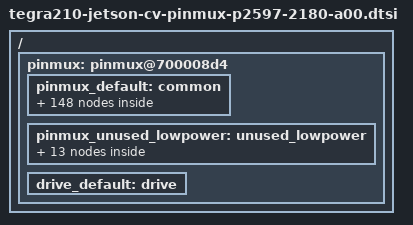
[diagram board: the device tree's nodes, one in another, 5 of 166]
/*
 * Copyright (c) 2015, NVIDIA CORPORATION.  All rights reserved.
 *
 * This program is free software; you can redistribute it and/or modify
 * it under the terms of the GNU General Public License as published by
 * the Free Software Foundation; either version 2 of the License, or
 * (at your option) any later version.
 *
 * This program is distributed in the hope that it will be useful, but WITHOUT
 * ANY WARRANTY; without even the implied warranty of MERCHANTABILITY or
 * FITNESS FOR A PARTICULAR PURPOSE.  See the GNU General Public License for
 * more details.
 *
 * You should have received a copy of the GNU General Public License along
 * with this program; if not, write to the Free Software Foundation, Inc.,
 * 51 Franklin Street, Fifth Floor, Boston, MA  02110-1301, USA.
 */

#include <dt-bindings/pinctrl/pinctrl-tegra.h>

/ {
	pinmux: pinmux@700008d4 {
		status = "okay";
		pinctrl-names = "default", "drive", "unused";
		pinctrl-0 = <&pinmux_default>;
		pinctrl-1 = <&drive_default>;
		pinctrl-2 = <&pinmux_unused_lowpower>;

		pinmux_default: common {
			/* SFIO Pin Configuration */
			aud_mclk {
				nvidia,pins = "aud_mclk";
				nvidia,function = "aud";
				nvidia,pull = <TEGRA_PIN_PULL_NONE>;
				nvidia,tristate = <TEGRA_PIN_DISABLE>;
				nvidia,enable-input = <TEGRA_PIN_DISABLE>;
			};

			dap1_din {
				nvidia,pins = "dap1_din";
				nvidia,function = "i2s1";
				nvidia,pull = <TEGRA_PIN_PULL_NONE>;
				nvidia,tristate = <TEGRA_PIN_DISABLE>;
				nvidia,enable-input = <TEGRA_PIN_ENABLE>;
			};

			dap1_dout {
				nvidia,pins = "dap1_dout";
				nvidia,function = "i2s1";
				nvidia,pull = <TEGRA_PIN_PULL_NONE>;
				nvidia,tristate = <TEGRA_PIN_DISABLE>;
				nvidia,enable-input = <TEGRA_PIN_ENABLE>;
			};

			dap1_fs {
				nvidia,pins = "dap1_fs";
				nvidia,function = "i2s1";
				nvidia,pull = <TEGRA_PIN_PULL_NONE>;
				nvidia,tristate = <TEGRA_PIN_DISABLE>;
				nvidia,enable-input = <TEGRA_PIN_ENABLE>;
			};

			dap1_sclk {
				nvidia,pins = "dap1_sclk";
				nvidia,function = "i2s1";
				nvidia,pull = <TEGRA_PIN_PULL_NONE>;
				nvidia,tristate = <TEGRA_PIN_DISABLE>;
				nvidia,enable-input = <TEGRA_PIN_ENABLE>;
			};

			pk0 {
				nvidia,pins = "pk0";
				nvidia,function = "i2s5b";
				nvidia,pull = <TEGRA_PIN_PULL_NONE>;
				nvidia,tristate = <TEGRA_PIN_DISABLE>;
				nvidia,enable-input = <TEGRA_PIN_ENABLE>;
			};

			pk1 {
				nvidia,pins = "pk1";
				nvidia,function = "i2s5b";
				nvidia,pull = <TEGRA_PIN_PULL_NONE>;
				nvidia,tristate = <TEGRA_PIN_DISABLE>;
				nvidia,enable-input = <TEGRA_PIN_ENABLE>;
			};

			pk2 {
				nvidia,pins = "pk2";
				nvidia,function = "i2s5b";
				nvidia,pull = <TEGRA_PIN_PULL_NONE>;
				nvidia,tristate = <TEGRA_PIN_DISABLE>;
				nvidia,enable-input = <TEGRA_PIN_ENABLE>;
			};

			pk3 {
				nvidia,pins = "pk3";
				nvidia,function = "i2s5b";
				nvidia,pull = <TEGRA_PIN_PULL_NONE>;
				nvidia,tristate = <TEGRA_PIN_DISABLE>;
				nvidia,enable-input = <TEGRA_PIN_ENABLE>;
			};

			dmic1_clk {
				nvidia,pins = "dmic1_clk";
				nvidia,function = "i2s3";
				nvidia,pull = <TEGRA_PIN_PULL_NONE>;
				nvidia,tristate = <TEGRA_PIN_DISABLE>;
				nvidia,enable-input = <TEGRA_PIN_ENABLE>;
			};

			dmic1_dat {
				nvidia,pins = "dmic1_dat";
				nvidia,function = "i2s3";
				nvidia,pull = <TEGRA_PIN_PULL_NONE>;
				nvidia,tristate = <TEGRA_PIN_DISABLE>;
				nvidia,enable-input = <TEGRA_PIN_ENABLE>;
			};

			dmic2_clk {
				nvidia,pins = "dmic2_clk";
				nvidia,function = "i2s3";
				nvidia,pull = <TEGRA_PIN_PULL_NONE>;
				nvidia,tristate = <TEGRA_PIN_DISABLE>;
				nvidia,enable-input = <TEGRA_PIN_ENABLE>;
			};

			dmic2_dat {
				nvidia,pins = "dmic2_dat";
				nvidia,function = "i2s3";
				nvidia,pull = <TEGRA_PIN_PULL_NONE>;
				nvidia,tristate = <TEGRA_PIN_DISABLE>;
				nvidia,enable-input = <TEGRA_PIN_ENABLE>;
			};

			dap4_din {
				nvidia,pins = "dap4_din";
				nvidia,function = "i2s4b";
				nvidia,pull = <TEGRA_PIN_PULL_NONE>;
				nvidia,tristate = <TEGRA_PIN_DISABLE>;
				nvidia,enable-input = <TEGRA_PIN_ENABLE>;
			};

			dap4_dout {
				nvidia,pins = "dap4_dout";
				nvidia,function = "i2s4b";
				nvidia,pull = <TEGRA_PIN_PULL_NONE>;
				nvidia,tristate = <TEGRA_PIN_DISABLE>;
				nvidia,enable-input = <TEGRA_PIN_ENABLE>;
			};

			dap4_fs {
				nvidia,pins = "dap4_fs";
				nvidia,function = "i2s4b";
				nvidia,pull = <TEGRA_PIN_PULL_NONE>;
				nvidia,tristate = <TEGRA_PIN_DISABLE>;
				nvidia,enable-input = <TEGRA_PIN_ENABLE>;
			};

			dap4_sclk {
				nvidia,pins = "dap4_sclk";
				nvidia,function = "i2s4b";
				nvidia,pull = <TEGRA_PIN_PULL_NONE>;
				nvidia,tristate = <TEGRA_PIN_DISABLE>;
				nvidia,enable-input = <TEGRA_PIN_ENABLE>;
			};

			dmic3_clk {
				nvidia,pins = "dmic3_clk";
				nvidia,function = "dmic3";
				nvidia,pull = <TEGRA_PIN_PULL_NONE>;
				nvidia,tristate = <TEGRA_PIN_DISABLE>;
				nvidia,enable-input = <TEGRA_PIN_DISABLE>;
			};

			dmic3_dat {
				nvidia,pins = "dmic3_dat";
				nvidia,function = "dmic3";
				nvidia,pull = <TEGRA_PIN_PULL_UP>;
				nvidia,tristate = <TEGRA_PIN_DISABLE>;
				nvidia,enable-input = <TEGRA_PIN_ENABLE>;
			};

			gen1_i2c_scl {
				nvidia,pins = "gen1_i2c_scl";
				nvidia,function = "i2c1";
				nvidia,pull = <TEGRA_PIN_PULL_NONE>;
				nvidia,tristate = <TEGRA_PIN_DISABLE>;
				nvidia,enable-input = <TEGRA_PIN_ENABLE>;
				nvidia,io-high-voltage = <TEGRA_PIN_DISABLE>;
			};

			gen1_i2c_sda {
				nvidia,pins = "gen1_i2c_sda";
				nvidia,function = "i2c1";
				nvidia,pull = <TEGRA_PIN_PULL_NONE>;
				nvidia,tristate = <TEGRA_PIN_DISABLE>;
				nvidia,enable-input = <TEGRA_PIN_ENABLE>;
				nvidia,io-high-voltage = <TEGRA_PIN_DISABLE>;
			};

			gen2_i2c_scl {
				nvidia,pins = "gen2_i2c_scl";
				nvidia,function = "i2c2";
				nvidia,pull = <TEGRA_PIN_PULL_NONE>;
				nvidia,tristate = <TEGRA_PIN_DISABLE>;
				nvidia,enable-input = <TEGRA_PIN_ENABLE>;
				nvidia,io-high-voltage = <TEGRA_PIN_ENABLE>;
			};

			gen2_i2c_sda {
				nvidia,pins = "gen2_i2c_sda";
				nvidia,function = "i2c2";
				nvidia,pull = <TEGRA_PIN_PULL_NONE>;
				nvidia,tristate = <TEGRA_PIN_DISABLE>;
				nvidia,enable-input = <TEGRA_PIN_ENABLE>;
				nvidia,io-high-voltage = <TEGRA_PIN_ENABLE>;
			};

			cam_i2c_scl {
				nvidia,pins = "cam_i2c_scl";
				nvidia,function = "i2cvi";
				nvidia,pull = <TEGRA_PIN_PULL_NONE>;
				nvidia,tristate = <TEGRA_PIN_DISABLE>;
				nvidia,enable-input = <TEGRA_PIN_ENABLE>;
				nvidia,io-high-voltage = <TEGRA_PIN_DISABLE>;
			};

			cam_i2c_sda {
				nvidia,pins = "cam_i2c_sda";
				nvidia,function = "i2cvi";
				nvidia,pull = <TEGRA_PIN_PULL_NONE>;
				nvidia,tristate = <TEGRA_PIN_DISABLE>;
				nvidia,enable-input = <TEGRA_PIN_ENABLE>;
				nvidia,io-high-voltage = <TEGRA_PIN_DISABLE>;
			};

			cam1_mclk {
				nvidia,pins = "cam1_mclk";
				nvidia,function = "extperiph3";
				nvidia,pull = <TEGRA_PIN_PULL_NONE>;
				nvidia,tristate = <TEGRA_PIN_DISABLE>;
				nvidia,enable-input = <TEGRA_PIN_DISABLE>;
			};

			cam2_mclk {
				nvidia,pins = "cam2_mclk";
				nvidia,function = "extperiph3";
				nvidia,pull = <TEGRA_PIN_PULL_NONE>;
				nvidia,tristate = <TEGRA_PIN_DISABLE>;
				nvidia,enable-input = <TEGRA_PIN_DISABLE>;
			};

			pex_l0_clkreq_n {
				nvidia,pins = "pex_l0_clkreq_n";
				nvidia,function = "pe0";
				nvidia,pull = <TEGRA_PIN_PULL_NONE>;
				nvidia,tristate = <TEGRA_PIN_DISABLE>;
				nvidia,enable-input = <TEGRA_PIN_ENABLE>;
				nvidia,io-high-voltage = <TEGRA_PIN_ENABLE>;
			};

			pex_l0_rst_n {
				nvidia,pins = "pex_l0_rst_n";
				nvidia,function = "pe0";
				nvidia,pull = <TEGRA_PIN_PULL_NONE>;
				nvidia,tristate = <TEGRA_PIN_DISABLE>;
				nvidia,enable-input = <TEGRA_PIN_DISABLE>;
				nvidia,io-high-voltage = <TEGRA_PIN_ENABLE>;
			};

			pex_l1_clkreq_n {
				nvidia,pins = "pex_l1_clkreq_n";
				nvidia,function = "pe1";
				nvidia,pull = <TEGRA_PIN_PULL_NONE>;
				nvidia,tristate = <TEGRA_PIN_DISABLE>;
				nvidia,enable-input = <TEGRA_PIN_ENABLE>;
				nvidia,io-high-voltage = <TEGRA_PIN_ENABLE>;
			};

			pex_l1_rst_n {
				nvidia,pins = "pex_l1_rst_n";
				nvidia,function = "pe1";
				nvidia,pull = <TEGRA_PIN_PULL_NONE>;
				nvidia,tristate = <TEGRA_PIN_DISABLE>;
				nvidia,enable-input = <TEGRA_PIN_DISABLE>;
				nvidia,io-high-voltage = <TEGRA_PIN_ENABLE>;
			};

			pex_wake_n {
				nvidia,pins = "pex_wake_n";
				nvidia,function = "pe";
				nvidia,pull = <TEGRA_PIN_PULL_NONE>;
				nvidia,tristate = <TEGRA_PIN_DISABLE>;
				nvidia,enable-input = <TEGRA_PIN_ENABLE>;
				nvidia,io-high-voltage = <TEGRA_PIN_ENABLE>;
			};

			pa6 {
				nvidia,pins = "pa6";
				nvidia,function = "sata";
				nvidia,pull = <TEGRA_PIN_PULL_NONE>;
				nvidia,tristate = <TEGRA_PIN_DISABLE>;
				nvidia,enable-input = <TEGRA_PIN_DISABLE>;
			};

			sdmmc1_clk {
				nvidia,pins = "sdmmc1_clk";
				nvidia,function = "sdmmc1";
				nvidia,pull = <TEGRA_PIN_PULL_NONE>;
				nvidia,tristate = <TEGRA_PIN_DISABLE>;
				nvidia,enable-input = <TEGRA_PIN_ENABLE>;
			};

			sdmmc1_cmd {
				nvidia,pins = "sdmmc1_cmd";
				nvidia,function = "sdmmc1";
				nvidia,pull = <TEGRA_PIN_PULL_UP>;
				nvidia,tristate = <TEGRA_PIN_DISABLE>;
				nvidia,enable-input = <TEGRA_PIN_ENABLE>;
			};

			sdmmc1_dat0 {
				nvidia,pins = "sdmmc1_dat0";
				nvidia,function = "sdmmc1";
				nvidia,pull = <TEGRA_PIN_PULL_UP>;
				nvidia,tristate = <TEGRA_PIN_DISABLE>;
				nvidia,enable-input = <TEGRA_PIN_ENABLE>;
			};

			sdmmc1_dat1 {
				nvidia,pins = "sdmmc1_dat1";
				nvidia,function = "sdmmc1";
				nvidia,pull = <TEGRA_PIN_PULL_UP>;
				nvidia,tristate = <TEGRA_PIN_DISABLE>;
				nvidia,enable-input = <TEGRA_PIN_ENABLE>;
			};

			sdmmc1_dat2 {
				nvidia,pins = "sdmmc1_dat2";
				nvidia,function = "sdmmc1";
				nvidia,pull = <TEGRA_PIN_PULL_UP>;
				nvidia,tristate = <TEGRA_PIN_DISABLE>;
				nvidia,enable-input = <TEGRA_PIN_ENABLE>;
			};

			sdmmc1_dat3 {
				nvidia,pins = "sdmmc1_dat3";
				nvidia,function = "sdmmc1";
				nvidia,pull = <TEGRA_PIN_PULL_UP>;
				nvidia,tristate = <TEGRA_PIN_DISABLE>;
				nvidia,enable-input = <TEGRA_PIN_ENABLE>;
			};

			pz1 {
				nvidia,pins = "pz1";
				nvidia,function = "sdmmc1";
				nvidia,pull = <TEGRA_PIN_PULL_UP>;
				nvidia,tristate = <TEGRA_PIN_DISABLE>;
				nvidia,enable-input = <TEGRA_PIN_ENABLE>;
			};

			pz4 {
				nvidia,pins = "pz4";
				nvidia,function = "sdmmc1";
				nvidia,pull = <TEGRA_PIN_PULL_UP>;
				nvidia,tristate = <TEGRA_PIN_DISABLE>;
				nvidia,enable-input = <TEGRA_PIN_ENABLE>;
			};

			sdmmc3_clk {
				nvidia,pins = "sdmmc3_clk";
				nvidia,function = "sdmmc3";
				nvidia,pull = <TEGRA_PIN_PULL_NONE>;
				nvidia,tristate = <TEGRA_PIN_DISABLE>;
				nvidia,enable-input = <TEGRA_PIN_ENABLE>;
			};

			sdmmc3_cmd {
				nvidia,pins = "sdmmc3_cmd";
				nvidia,function = "sdmmc3";
				nvidia,pull = <TEGRA_PIN_PULL_UP>;
				nvidia,tristate = <TEGRA_PIN_DISABLE>;
				nvidia,enable-input = <TEGRA_PIN_ENABLE>;
			};

			sdmmc3_dat0 {
				nvidia,pins = "sdmmc3_dat0";
				nvidia,function = "sdmmc3";
				nvidia,pull = <TEGRA_PIN_PULL_UP>;
				nvidia,tristate = <TEGRA_PIN_DISABLE>;
				nvidia,enable-input = <TEGRA_PIN_ENABLE>;
			};

			sdmmc3_dat1 {
				nvidia,pins = "sdmmc3_dat1";
				nvidia,function = "sdmmc3";
				nvidia,pull = <TEGRA_PIN_PULL_UP>;
				nvidia,tristate = <TEGRA_PIN_DISABLE>;
				nvidia,enable-input = <TEGRA_PIN_ENABLE>;
			};

			sdmmc3_dat2 {
				nvidia,pins = "sdmmc3_dat2";
				nvidia,function = "sdmmc3";
				nvidia,pull = <TEGRA_PIN_PULL_UP>;
				nvidia,tristate = <TEGRA_PIN_DISABLE>;
				nvidia,enable-input = <TEGRA_PIN_ENABLE>;
			};

			sdmmc3_dat3 {
				nvidia,pins = "sdmmc3_dat3";
				nvidia,function = "sdmmc3";
				nvidia,pull = <TEGRA_PIN_PULL_UP>;
				nvidia,tristate = <TEGRA_PIN_DISABLE>;
				nvidia,enable-input = <TEGRA_PIN_ENABLE>;
			};

			touch_clk {
				nvidia,pins = "touch_clk";
				nvidia,function = "touch";
				nvidia,pull = <TEGRA_PIN_PULL_NONE>;
				nvidia,tristate = <TEGRA_PIN_DISABLE>;
				nvidia,enable-input = <TEGRA_PIN_DISABLE>;
			};

			lcd_te {
				nvidia,pins = "lcd_te";
				nvidia,function = "displaya";
				nvidia,pull = <TEGRA_PIN_PULL_DOWN>;
				nvidia,tristate = <TEGRA_PIN_DISABLE>;
				nvidia,enable-input = <TEGRA_PIN_ENABLE>;
			};

			lcd_bl_pwm {
				nvidia,pins = "lcd_bl_pwm";
				nvidia,function = "pwm0";
				nvidia,pull = <TEGRA_PIN_PULL_NONE>;
				nvidia,tristate = <TEGRA_PIN_DISABLE>;
				nvidia,enable-input = <TEGRA_PIN_DISABLE>;
			};

			gen3_i2c_scl {
				nvidia,pins = "gen3_i2c_scl";
				nvidia,function = "i2c3";
				nvidia,pull = <TEGRA_PIN_PULL_NONE>;
				nvidia,tristate = <TEGRA_PIN_DISABLE>;
				nvidia,enable-input = <TEGRA_PIN_ENABLE>;
				nvidia,io-high-voltage = <TEGRA_PIN_DISABLE>;
			};

			gen3_i2c_sda {
				nvidia,pins = "gen3_i2c_sda";
				nvidia,function = "i2c3";
				nvidia,pull = <TEGRA_PIN_PULL_NONE>;
				nvidia,tristate = <TEGRA_PIN_DISABLE>;
				nvidia,enable-input = <TEGRA_PIN_ENABLE>;
				nvidia,io-high-voltage = <TEGRA_PIN_DISABLE>;
			};

			pe7 {
				nvidia,pins = "pe7";
				nvidia,function = "pwm3";
				nvidia,pull = <TEGRA_PIN_PULL_NONE>;
				nvidia,tristate = <TEGRA_PIN_DISABLE>;
				nvidia,enable-input = <TEGRA_PIN_DISABLE>;
			};

			uart1_tx {
				nvidia,pins = "uart1_tx";
				nvidia,function = "uarta";
				nvidia,pull = <TEGRA_PIN_PULL_NONE>;
				nvidia,tristate = <TEGRA_PIN_DISABLE>;
				nvidia,enable-input = <TEGRA_PIN_DISABLE>;
			};

			uart1_rx {
				nvidia,pins = "uart1_rx";
				nvidia,function = "uarta";
				nvidia,pull = <TEGRA_PIN_PULL_UP>;
				nvidia,tristate = <TEGRA_PIN_DISABLE>;
				nvidia,enable-input = <TEGRA_PIN_ENABLE>;
			};

			uart1_rts {
				nvidia,pins = "uart1_rts";
				nvidia,function = "uarta";
				nvidia,pull = <TEGRA_PIN_PULL_NONE>;
				nvidia,tristate = <TEGRA_PIN_DISABLE>;
				nvidia,enable-input = <TEGRA_PIN_DISABLE>;
			};

			uart1_cts {
				nvidia,pins = "uart1_cts";
				nvidia,function = "uarta";
				nvidia,pull = <TEGRA_PIN_PULL_UP>;
				nvidia,tristate = <TEGRA_PIN_DISABLE>;
				nvidia,enable-input = <TEGRA_PIN_ENABLE>;
			};

			uart3_tx {
				nvidia,pins = "uart3_tx";
				nvidia,function = "uartc";
				nvidia,pull = <TEGRA_PIN_PULL_NONE>;
				nvidia,tristate = <TEGRA_PIN_DISABLE>;
				nvidia,enable-input = <TEGRA_PIN_DISABLE>;
			};

			uart3_rx {
				nvidia,pins = "uart3_rx";
				nvidia,function = "uartc";
				nvidia,pull = <TEGRA_PIN_PULL_UP>;
				nvidia,tristate = <TEGRA_PIN_DISABLE>;
				nvidia,enable-input = <TEGRA_PIN_ENABLE>;
			};

			uart3_rts {
				nvidia,pins = "uart3_rts";
				nvidia,function = "uartc";
				nvidia,pull = <TEGRA_PIN_PULL_NONE>;
				nvidia,tristate = <TEGRA_PIN_DISABLE>;
				nvidia,enable-input = <TEGRA_PIN_DISABLE>;
			};

			uart3_cts {
				nvidia,pins = "uart3_cts";
				nvidia,function = "uartc";
				nvidia,pull = <TEGRA_PIN_PULL_UP>;
				nvidia,tristate = <TEGRA_PIN_DISABLE>;
				nvidia,enable-input = <TEGRA_PIN_ENABLE>;
			};

			uart2_tx {
				nvidia,pins = "uart2_tx";
				nvidia,function = "uartb";
				nvidia,pull = <TEGRA_PIN_PULL_NONE>;
				nvidia,tristate = <TEGRA_PIN_DISABLE>;
				nvidia,enable-input = <TEGRA_PIN_DISABLE>;
			};

			uart2_rx {
				nvidia,pins = "uart2_rx";
				nvidia,function = "uartb";
				nvidia,pull = <TEGRA_PIN_PULL_UP>;
				nvidia,tristate = <TEGRA_PIN_DISABLE>;
				nvidia,enable-input = <TEGRA_PIN_ENABLE>;
			};

			uart2_rts {
				nvidia,pins = "uart2_rts";
				nvidia,function = "uartb";
				nvidia,pull = <TEGRA_PIN_PULL_NONE>;
				nvidia,tristate = <TEGRA_PIN_DISABLE>;
				nvidia,enable-input = <TEGRA_PIN_DISABLE>;
			};

			uart2_cts {
				nvidia,pins = "uart2_cts";
				nvidia,function = "uartb";
				nvidia,pull = <TEGRA_PIN_PULL_UP>;
				nvidia,tristate = <TEGRA_PIN_DISABLE>;
				nvidia,enable-input = <TEGRA_PIN_ENABLE>;
			};

			jtag_rtck {
				nvidia,pins = "jtag_rtck";
				nvidia,function = "jtag";
				nvidia,pull = <TEGRA_PIN_PULL_NONE>;
				nvidia,tristate = <TEGRA_PIN_DISABLE>;
				nvidia,enable-input = <TEGRA_PIN_DISABLE>;
			};

			spi4_mosi {
				nvidia,pins = "spi4_mosi";
				nvidia,function = "spi4";
				nvidia,pull = <TEGRA_PIN_PULL_DOWN>;
				nvidia,tristate = <TEGRA_PIN_DISABLE>;
				nvidia,enable-input = <TEGRA_PIN_ENABLE>;
			};

			spi4_miso {
				nvidia,pins = "spi4_miso";
				nvidia,function = "spi4";
				nvidia,pull = <TEGRA_PIN_PULL_DOWN>;
				nvidia,tristate = <TEGRA_PIN_DISABLE>;
				nvidia,enable-input = <TEGRA_PIN_ENABLE>;
			};

			spi4_sck {
				nvidia,pins = "spi4_sck";
				nvidia,function = "spi4";
				nvidia,pull = <TEGRA_PIN_PULL_DOWN>;
				nvidia,tristate = <TEGRA_PIN_DISABLE>;
				nvidia,enable-input = <TEGRA_PIN_ENABLE>;
			};

			spi4_cs0 {
				nvidia,pins = "spi4_cs0";
				nvidia,function = "spi4";
				nvidia,pull = <TEGRA_PIN_PULL_UP>;
				nvidia,tristate = <TEGRA_PIN_DISABLE>;
				nvidia,enable-input = <TEGRA_PIN_ENABLE>;
			};

			spi1_mosi {
				nvidia,pins = "spi1_mosi";
				nvidia,function = "spi1";
				nvidia,pull = <TEGRA_PIN_PULL_DOWN>;
				nvidia,tristate = <TEGRA_PIN_DISABLE>;
				nvidia,enable-input = <TEGRA_PIN_ENABLE>;
			};

			spi1_miso {
				nvidia,pins = "spi1_miso";
				nvidia,function = "spi1";
				nvidia,pull = <TEGRA_PIN_PULL_DOWN>;
				nvidia,tristate = <TEGRA_PIN_DISABLE>;
				nvidia,enable-input = <TEGRA_PIN_ENABLE>;
			};

			spi1_sck {
				nvidia,pins = "spi1_sck";
				nvidia,function = "spi1";
				nvidia,pull = <TEGRA_PIN_PULL_DOWN>;
				nvidia,tristate = <TEGRA_PIN_DISABLE>;
				nvidia,enable-input = <TEGRA_PIN_ENABLE>;
			};

			spi1_cs0 {
				nvidia,pins = "spi1_cs0";
				nvidia,function = "spi1";
				nvidia,pull = <TEGRA_PIN_PULL_UP>;
				nvidia,tristate = <TEGRA_PIN_DISABLE>;
				nvidia,enable-input = <TEGRA_PIN_ENABLE>;
			};

			spi1_cs1 {
				nvidia,pins = "spi1_cs1";
				nvidia,function = "spi1";
				nvidia,pull = <TEGRA_PIN_PULL_UP>;
				nvidia,tristate = <TEGRA_PIN_DISABLE>;
				nvidia,enable-input = <TEGRA_PIN_ENABLE>;
			};

			spi2_mosi {
				nvidia,pins = "spi2_mosi";
				nvidia,function = "spi2";
				nvidia,pull = <TEGRA_PIN_PULL_NONE>;
				nvidia,tristate = <TEGRA_PIN_DISABLE>;
				nvidia,enable-input = <TEGRA_PIN_ENABLE>;
			};

			spi2_miso {
				nvidia,pins = "spi2_miso";
				nvidia,function = "spi2";
				nvidia,pull = <TEGRA_PIN_PULL_NONE>;
				nvidia,tristate = <TEGRA_PIN_DISABLE>;
				nvidia,enable-input = <TEGRA_PIN_ENABLE>;
			};

			spi2_sck {
				nvidia,pins = "spi2_sck";
				nvidia,function = "spi2";
				nvidia,pull = <TEGRA_PIN_PULL_NONE>;
				nvidia,tristate = <TEGRA_PIN_DISABLE>;
				nvidia,enable-input = <TEGRA_PIN_ENABLE>;
			};

			spi2_cs0 {
				nvidia,pins = "spi2_cs0";
				nvidia,function = "spi2";
				nvidia,pull = <TEGRA_PIN_PULL_UP>;
				nvidia,tristate = <TEGRA_PIN_DISABLE>;
				nvidia,enable-input = <TEGRA_PIN_ENABLE>;
			};

			spi2_cs1 {
				nvidia,pins = "spi2_cs1";
				nvidia,function = "spi2";
				nvidia,pull = <TEGRA_PIN_PULL_UP>;
				nvidia,tristate = <TEGRA_PIN_DISABLE>;
				nvidia,enable-input = <TEGRA_PIN_ENABLE>;
			};

			usb_vbus_en0 {
				nvidia,pins = "usb_vbus_en0";
				nvidia,function = "usb";
				nvidia,pull = <TEGRA_PIN_PULL_NONE>;
				nvidia,tristate = <TEGRA_PIN_DISABLE>;
				nvidia,enable-input = <TEGRA_PIN_ENABLE>;
				nvidia,io-high-voltage = <TEGRA_PIN_ENABLE>;
			};

			usb_vbus_en1 {
				nvidia,pins = "usb_vbus_en1";
				nvidia,function = "usb";
				nvidia,pull = <TEGRA_PIN_PULL_NONE>;
				nvidia,tristate = <TEGRA_PIN_DISABLE>;
				nvidia,enable-input = <TEGRA_PIN_ENABLE>;
				nvidia,io-high-voltage = <TEGRA_PIN_ENABLE>;
			};

			dp_hpd0 {
				nvidia,pins = "dp_hpd0";
				nvidia,function = "dp";
				nvidia,pull = <TEGRA_PIN_PULL_DOWN>;
				nvidia,tristate = <TEGRA_PIN_DISABLE>;
				nvidia,enable-input = <TEGRA_PIN_ENABLE>;
			};

			hdmi_cec {
				nvidia,pins = "hdmi_cec";
				nvidia,function = "cec";
				nvidia,pull = <TEGRA_PIN_PULL_NONE>;
				nvidia,tristate = <TEGRA_PIN_DISABLE>;
				nvidia,enable-input = <TEGRA_PIN_ENABLE>;
				nvidia,io-high-voltage = <TEGRA_PIN_ENABLE>;
			};

			dap2_din {
				nvidia,pins = "dap2_din";
				nvidia,function = "i2s2";
				nvidia,pull = <TEGRA_PIN_PULL_NONE>;
				nvidia,tristate = <TEGRA_PIN_DISABLE>;
				nvidia,enable-input = <TEGRA_PIN_ENABLE>;
			};

			dap2_dout {
				nvidia,pins = "dap2_dout";
				nvidia,function = "i2s2";
				nvidia,pull = <TEGRA_PIN_PULL_NONE>;
				nvidia,tristate = <TEGRA_PIN_DISABLE>;
				nvidia,enable-input = <TEGRA_PIN_ENABLE>;
			};

			dap2_fs {
				nvidia,pins = "dap2_fs";
				nvidia,function = "i2s2";
				nvidia,pull = <TEGRA_PIN_PULL_NONE>;
				nvidia,tristate = <TEGRA_PIN_DISABLE>;
				nvidia,enable-input = <TEGRA_PIN_ENABLE>;
			};

			dap2_sclk {
				nvidia,pins = "dap2_sclk";
				nvidia,function = "i2s2";
				nvidia,pull = <TEGRA_PIN_PULL_NONE>;
				nvidia,tristate = <TEGRA_PIN_DISABLE>;
				nvidia,enable-input = <TEGRA_PIN_ENABLE>;
			};

			uart4_tx {
				nvidia,pins = "uart4_tx";
				nvidia,function = "uartd";
				nvidia,pull = <TEGRA_PIN_PULL_NONE>;
				nvidia,tristate = <TEGRA_PIN_DISABLE>;
				nvidia,enable-input = <TEGRA_PIN_DISABLE>;
			};

			uart4_rx {
				nvidia,pins = "uart4_rx";
				nvidia,function = "uartd";
				nvidia,pull = <TEGRA_PIN_PULL_NONE>;
				nvidia,tristate = <TEGRA_PIN_DISABLE>;
				nvidia,enable-input = <TEGRA_PIN_ENABLE>;
			};

			uart4_rts {
				nvidia,pins = "uart4_rts";
				nvidia,function = "uartd";
				nvidia,pull = <TEGRA_PIN_PULL_NONE>;
				nvidia,tristate = <TEGRA_PIN_DISABLE>;
				nvidia,enable-input = <TEGRA_PIN_DISABLE>;
			};

			uart4_cts {
				nvidia,pins = "uart4_cts";
				nvidia,function = "uartd";
				nvidia,pull = <TEGRA_PIN_PULL_NONE>;
				nvidia,tristate = <TEGRA_PIN_DISABLE>;
				nvidia,enable-input = <TEGRA_PIN_ENABLE>;
			};

			pwr_i2c_scl {
				nvidia,pins = "pwr_i2c_scl";
				nvidia,function = "i2cpmu";
				nvidia,pull = <TEGRA_PIN_PULL_NONE>;
				nvidia,tristate = <TEGRA_PIN_DISABLE>;
				nvidia,enable-input = <TEGRA_PIN_ENABLE>;
				nvidia,io-high-voltage = <TEGRA_PIN_DISABLE>;
			};

			pwr_i2c_sda {
				nvidia,pins = "pwr_i2c_sda";
				nvidia,function = "i2cpmu";
				nvidia,pull = <TEGRA_PIN_PULL_NONE>;
				nvidia,tristate = <TEGRA_PIN_DISABLE>;
				nvidia,enable-input = <TEGRA_PIN_ENABLE>;
				nvidia,io-high-voltage = <TEGRA_PIN_DISABLE>;
			};

			clk_32k_in {
				nvidia,pins = "clk_32k_in";
				nvidia,function = "clk";
				nvidia,pull = <TEGRA_PIN_PULL_NONE>;
				nvidia,tristate = <TEGRA_PIN_DISABLE>;
				nvidia,enable-input = <TEGRA_PIN_ENABLE>;
			};

			clk_32k_out {
				nvidia,pins = "clk_32k_out";
				nvidia,function = "soc";
				nvidia,pull = <TEGRA_PIN_PULL_UP>;
				nvidia,tristate = <TEGRA_PIN_DISABLE>;
				nvidia,enable-input = <TEGRA_PIN_ENABLE>;
			};

			dvfs_pwm {
				nvidia,pins = "dvfs_pwm";
				nvidia,function = "cldvfs";
				nvidia,pull = <TEGRA_PIN_PULL_NONE>;
				nvidia,tristate = <TEGRA_PIN_ENABLE>;
				nvidia,enable-input = <TEGRA_PIN_DISABLE>;
			};

			lcd_gpio2 {
				nvidia,pins = "lcd_gpio2";
				nvidia,function = "pwm1";
				nvidia,pull = <TEGRA_PIN_PULL_NONE>;
				nvidia,tristate = <TEGRA_PIN_DISABLE>;
				nvidia,enable-input = <TEGRA_PIN_DISABLE>;
			};

			shutdown {
				nvidia,pins = "shutdown";
				nvidia,function = "shutdown";
				nvidia,pull = <TEGRA_PIN_PULL_NONE>;
				nvidia,tristate = <TEGRA_PIN_DISABLE>;
				nvidia,enable-input = <TEGRA_PIN_DISABLE>;
			};

			pz5 {
				nvidia,pins = "pz5";
				nvidia,function = "soc";
				nvidia,pull = <TEGRA_PIN_PULL_UP>;
				nvidia,tristate = <TEGRA_PIN_DISABLE>;
				nvidia,enable-input = <TEGRA_PIN_ENABLE>;
			};

			core_pwr_req {
				nvidia,pins = "core_pwr_req";
				nvidia,function = "core";
				nvidia,pull = <TEGRA_PIN_PULL_NONE>;
				nvidia,tristate = <TEGRA_PIN_DISABLE>;
				nvidia,enable-input = <TEGRA_PIN_DISABLE>;
			};

			cpu_pwr_req {
				nvidia,pins = "cpu_pwr_req";
				nvidia,function = "cpu";
				nvidia,pull = <TEGRA_PIN_PULL_NONE>;
				nvidia,tristate = <TEGRA_PIN_DISABLE>;
				nvidia,enable-input = <TEGRA_PIN_DISABLE>;
			};

			pwr_int_n {
				nvidia,pins = "pwr_int_n";
				nvidia,function = "pmi";
				nvidia,pull = <TEGRA_PIN_PULL_UP>;
				nvidia,tristate = <TEGRA_PIN_DISABLE>;
				nvidia,enable-input = <TEGRA_PIN_ENABLE>;
			};

			/* GPIO Pin Configuration */
			gpio_x1_aud_pbb3 {
				nvidia,pins = "gpio_x1_aud_pbb3";
				nvidia,function = "rsvd0";
				nvidia,pull = <TEGRA_PIN_PULL_NONE>;
				nvidia,tristate = <TEGRA_PIN_DISABLE>;
				nvidia,enable-input = <TEGRA_PIN_DISABLE>;
			};

			pe6 {
				nvidia,pins = "pe6";
				nvidia,function = "rsvd0";
				nvidia,pull = <TEGRA_PIN_PULL_UP>;
				nvidia,tristate = <TEGRA_PIN_DISABLE>;
				nvidia,enable-input = <TEGRA_PIN_ENABLE>;
			};

			cam_rst_ps4 {
				nvidia,pins = "cam_rst_ps4";
				nvidia,function = "rsvd1";
				nvidia,pull = <TEGRA_PIN_PULL_NONE>;
				nvidia,tristate = <TEGRA_PIN_DISABLE>;
				nvidia,enable-input = <TEGRA_PIN_DISABLE>;
			};

			cam_af_en_ps5 {
				nvidia,pins = "cam_af_en_ps5";
				nvidia,function = "rsvd2";
				nvidia,pull = <TEGRA_PIN_PULL_NONE>;
				nvidia,tristate = <TEGRA_PIN_DISABLE>;
				nvidia,enable-input = <TEGRA_PIN_DISABLE>;
			};

			cam_flash_en_ps6 {
				nvidia,pins = "cam_flash_en_ps6";
				nvidia,function = "rsvd2";
				nvidia,pull = <TEGRA_PIN_PULL_NONE>;
				nvidia,tristate = <TEGRA_PIN_DISABLE>;
				nvidia,enable-input = <TEGRA_PIN_DISABLE>;
			};

			cam1_pwdn_ps7 {
				nvidia,pins = "cam1_pwdn_ps7";
				nvidia,function = "rsvd1";
				nvidia,pull = <TEGRA_PIN_PULL_NONE>;
				nvidia,tristate = <TEGRA_PIN_DISABLE>;
				nvidia,enable-input = <TEGRA_PIN_DISABLE>;
			};

			cam2_pwdn_pt0 {
				nvidia,pins = "cam2_pwdn_pt0";
				nvidia,function = "rsvd1";
				nvidia,pull = <TEGRA_PIN_PULL_NONE>;
				nvidia,tristate = <TEGRA_PIN_DISABLE>;
				nvidia,enable-input = <TEGRA_PIN_DISABLE>;
			};

			cam1_strobe_pt1 {
				nvidia,pins = "cam1_strobe_pt1";
				nvidia,function = "rsvd1";
				nvidia,pull = <TEGRA_PIN_PULL_NONE>;
				nvidia,tristate = <TEGRA_PIN_DISABLE>;
				nvidia,enable-input = <TEGRA_PIN_DISABLE>;
			};

			pz3 {
				nvidia,pins = "pz3";
				nvidia,function = "rsvd1";
				nvidia,pull = <TEGRA_PIN_PULL_NONE>;
				nvidia,tristate = <TEGRA_PIN_DISABLE>;
				nvidia,enable-input = <TEGRA_PIN_DISABLE>;
			};

			nfc_en_pi0 {
				nvidia,pins = "nfc_en_pi0";
				nvidia,function = "rsvd0";
				nvidia,pull = <TEGRA_PIN_PULL_NONE>;
				nvidia,tristate = <TEGRA_PIN_DISABLE>;
				nvidia,enable-input = <TEGRA_PIN_DISABLE>;
			};

			touch_int_px1 {
				nvidia,pins = "touch_int_px1";
				nvidia,function = "rsvd0";
				nvidia,pull = <TEGRA_PIN_PULL_UP>;
				nvidia,tristate = <TEGRA_PIN_DISABLE>;
				nvidia,enable-input = <TEGRA_PIN_ENABLE>;
			};

			touch_rst_pv6 {
				nvidia,pins = "touch_rst_pv6";
				nvidia,function = "rsvd0";
				nvidia,pull = <TEGRA_PIN_PULL_NONE>;
				nvidia,tristate = <TEGRA_PIN_DISABLE>;
				nvidia,enable-input = <TEGRA_PIN_DISABLE>;
			};

			lcd_bl_en_pv1 {
				nvidia,pins = "lcd_bl_en_pv1";
				nvidia,function = "rsvd0";
				nvidia,pull = <TEGRA_PIN_PULL_NONE>;
				nvidia,tristate = <TEGRA_PIN_DISABLE>;
				nvidia,enable-input = <TEGRA_PIN_DISABLE>;
			};

			lcd_rst_pv2 {
				nvidia,pins = "lcd_rst_pv2";
				nvidia,function = "rsvd0";
				nvidia,pull = <TEGRA_PIN_PULL_NONE>;
				nvidia,tristate = <TEGRA_PIN_DISABLE>;
				nvidia,enable-input = <TEGRA_PIN_DISABLE>;
			};

			button_power_on_px5 {
				nvidia,pins = "button_power_on_px5";
				nvidia,function = "rsvd0";
				nvidia,pull = <TEGRA_PIN_PULL_UP>;
				nvidia,tristate = <TEGRA_PIN_DISABLE>;
				nvidia,enable-input = <TEGRA_PIN_ENABLE>;
			};

			button_vol_up_px6 {
				nvidia,pins = "button_vol_up_px6";
				nvidia,function = "rsvd0";
				nvidia,pull = <TEGRA_PIN_PULL_UP>;
				nvidia,tristate = <TEGRA_PIN_DISABLE>;
				nvidia,enable-input = <TEGRA_PIN_ENABLE>;
			};

			button_vol_down_px7 {
				nvidia,pins = "button_vol_down_px7";
				nvidia,function = "rsvd0";
				nvidia,pull = <TEGRA_PIN_PULL_UP>;
				nvidia,tristate = <TEGRA_PIN_DISABLE>;
				nvidia,enable-input = <TEGRA_PIN_ENABLE>;
			};

			button_slide_sw_py0 {
				nvidia,pins = "button_slide_sw_py0";
				nvidia,function = "rsvd0";
				nvidia,pull = <TEGRA_PIN_PULL_UP>;
				nvidia,tristate = <TEGRA_PIN_DISABLE>;
				nvidia,enable-input = <TEGRA_PIN_ENABLE>;
			};

			lcd_gpio1_pv3 {
				nvidia,pins = "lcd_gpio1_pv3";
				nvidia,function = "rsvd1";
				nvidia,pull = <TEGRA_PIN_PULL_NONE>;
				nvidia,tristate = <TEGRA_PIN_DISABLE>;
				nvidia,enable-input = <TEGRA_PIN_ENABLE>;
			};

			pk7 {
				nvidia,pins = "pk7";
				nvidia,function = "rsvd1";
				nvidia,pull = <TEGRA_PIN_PULL_UP>;
				nvidia,tristate = <TEGRA_PIN_DISABLE>;
				nvidia,enable-input = <TEGRA_PIN_ENABLE>;
			};

			als_prox_int_px3 {
				nvidia,pins = "als_prox_int_px3";
				nvidia,function = "rsvd0";
				nvidia,pull = <TEGRA_PIN_PULL_UP>;
				nvidia,tristate = <TEGRA_PIN_DISABLE>;
				nvidia,enable-input = <TEGRA_PIN_ENABLE>;
			};

			motion_int_px2 {
				nvidia,pins = "motion_int_px2";
				nvidia,function = "rsvd0";
				nvidia,pull = <TEGRA_PIN_PULL_UP>;
				nvidia,tristate = <TEGRA_PIN_DISABLE>;
				nvidia,enable-input = <TEGRA_PIN_ENABLE>;
			};

			nfc_int_pi1 {
				nvidia,pins = "nfc_int_pi1";
				nvidia,function = "rsvd0";
				nvidia,pull = <TEGRA_PIN_PULL_UP>;
				nvidia,tristate = <TEGRA_PIN_DISABLE>;
				nvidia,enable-input = <TEGRA_PIN_ENABLE>;
			};

			ap_wake_nfc_ph7 {
				nvidia,pins = "ap_wake_nfc_ph7";
				nvidia,function = "rsvd0";
				nvidia,pull = <TEGRA_PIN_PULL_NONE>;
				nvidia,tristate = <TEGRA_PIN_DISABLE>;
				nvidia,enable-input = <TEGRA_PIN_DISABLE>;
			};

			gps_en_pi2 {
				nvidia,pins = "gps_en_pi2";
				nvidia,function = "rsvd0";
				nvidia,pull = <TEGRA_PIN_PULL_NONE>;
				nvidia,tristate = <TEGRA_PIN_DISABLE>;
				nvidia,enable-input = <TEGRA_PIN_DISABLE>;
			};

			ph6 {
				nvidia,pins = "ph6";
				nvidia,function = "rsvd0";
				nvidia,pull = <TEGRA_PIN_PULL_UP>;
				nvidia,tristate = <TEGRA_PIN_DISABLE>;
				nvidia,enable-input = <TEGRA_PIN_ENABLE>;
			};

			pk5 {
				nvidia,pins = "pk5";
				nvidia,function = "rsvd1";
				nvidia,pull = <TEGRA_PIN_PULL_NONE>;
				nvidia,tristate = <TEGRA_PIN_DISABLE>;
				nvidia,enable-input = <TEGRA_PIN_DISABLE>;
			};

			ap_ready_pv5 {
				nvidia,pins = "ap_ready_pv5";
				nvidia,function = "rsvd0";
				nvidia,pull = <TEGRA_PIN_PULL_NONE>;
				nvidia,tristate = <TEGRA_PIN_DISABLE>;
				nvidia,enable-input = <TEGRA_PIN_DISABLE>;
			};

			modem_wake_ap_px0 {
				nvidia,pins = "modem_wake_ap_px0";
				nvidia,function = "rsvd0";
				nvidia,pull = <TEGRA_PIN_PULL_UP>;
				nvidia,tristate = <TEGRA_PIN_DISABLE>;
				nvidia,enable-input = <TEGRA_PIN_ENABLE>;
			};

			pk4 {
				nvidia,pins = "pk4";
				nvidia,function = "rsvd1";
				nvidia,pull = <TEGRA_PIN_PULL_UP>;
				nvidia,tristate = <TEGRA_PIN_DISABLE>;
				nvidia,enable-input = <TEGRA_PIN_ENABLE>;
			};

			pk6 {
				nvidia,pins = "pk6";
				nvidia,function = "rsvd1";
				nvidia,pull = <TEGRA_PIN_PULL_UP>;
				nvidia,tristate = <TEGRA_PIN_DISABLE>;
				nvidia,enable-input = <TEGRA_PIN_ENABLE>;
			};

			pl1 {
				nvidia,pins = "pl1";
				nvidia,function = "rsvd1";
				nvidia,pull = <TEGRA_PIN_PULL_UP>;
				nvidia,tristate = <TEGRA_PIN_DISABLE>;
				nvidia,enable-input = <TEGRA_PIN_ENABLE>;
			};

			pz2 {
				nvidia,pins = "pz2";
				nvidia,function = "rsvd2";
				nvidia,pull = <TEGRA_PIN_PULL_UP>;
				nvidia,tristate = <TEGRA_PIN_DISABLE>;
				nvidia,enable-input = <TEGRA_PIN_ENABLE>;
			};

			pz0 {
				nvidia,pins = "pz0";
				nvidia,function = "rsvd1";
				nvidia,pull = <TEGRA_PIN_PULL_UP>;
				nvidia,tristate = <TEGRA_PIN_DISABLE>;
				nvidia,enable-input = <TEGRA_PIN_ENABLE>;
			};

			hdmi_int_dp_hpd_pcc1 {
				nvidia,pins = "hdmi_int_dp_hpd_pcc1";
				nvidia,function = "rsvd1";
				nvidia,pull = <TEGRA_PIN_PULL_DOWN>;
				nvidia,tristate = <TEGRA_PIN_DISABLE>;
				nvidia,enable-input = <TEGRA_PIN_ENABLE>;
				nvidia,io-high-voltage = <TEGRA_PIN_DISABLE>;
			};

			wifi_en_ph0 {
				nvidia,pins = "wifi_en_ph0";
				nvidia,function = "rsvd0";
				nvidia,pull = <TEGRA_PIN_PULL_NONE>;
				nvidia,tristate = <TEGRA_PIN_DISABLE>;
				nvidia,enable-input = <TEGRA_PIN_DISABLE>;
			};

			wifi_rst_ph1 {
				nvidia,pins = "wifi_rst_ph1";
				nvidia,function = "rsvd0";
				nvidia,pull = <TEGRA_PIN_PULL_NONE>;
				nvidia,tristate = <TEGRA_PIN_DISABLE>;
				nvidia,enable-input = <TEGRA_PIN_DISABLE>;
			};

			wifi_wake_ap_ph2 {
				nvidia,pins = "wifi_wake_ap_ph2";
				nvidia,function = "rsvd0";
				nvidia,pull = <TEGRA_PIN_PULL_UP>;
				nvidia,tristate = <TEGRA_PIN_DISABLE>;
				nvidia,enable-input = <TEGRA_PIN_ENABLE>;
			};

			ap_wake_bt_ph3 {
				nvidia,pins = "ap_wake_bt_ph3";
				nvidia,function = "rsvd0";
				nvidia,pull = <TEGRA_PIN_PULL_NONE>;
				nvidia,tristate = <TEGRA_PIN_DISABLE>;
				nvidia,enable-input = <TEGRA_PIN_DISABLE>;
			};

			bt_rst_ph4 {
				nvidia,pins = "bt_rst_ph4";
				nvidia,function = "rsvd0";
				nvidia,pull = <TEGRA_PIN_PULL_NONE>;
				nvidia,tristate = <TEGRA_PIN_DISABLE>;
				nvidia,enable-input = <TEGRA_PIN_DISABLE>;
			};

			bt_wake_ap_ph5 {
				nvidia,pins = "bt_wake_ap_ph5";
				nvidia,function = "rsvd0";
				nvidia,pull = <TEGRA_PIN_PULL_UP>;
				nvidia,tristate = <TEGRA_PIN_DISABLE>;
				nvidia,enable-input = <TEGRA_PIN_ENABLE>;
			};

			dvfs_clk_pbb2 {
				nvidia,pins = "dvfs_clk_pbb2";
				nvidia,function = "rsvd0";
				nvidia,pull = <TEGRA_PIN_PULL_NONE>;
				nvidia,tristate = <TEGRA_PIN_DISABLE>;
				nvidia,enable-input = <TEGRA_PIN_DISABLE>;
			};

			button_home_py1 {
				nvidia,pins = "button_home_py1";
				nvidia,function = "rsvd0";
				nvidia,pull = <TEGRA_PIN_PULL_UP>;
				nvidia,tristate = <TEGRA_PIN_DISABLE>;
				nvidia,enable-input = <TEGRA_PIN_ENABLE>;
			};

			sata_led_active_pa5 {
				nvidia,pins = "sata_led_active_pa5";
				nvidia,function = "rsvd1";
				nvidia,pull = <TEGRA_PIN_PULL_UP>;
				nvidia,tristate = <TEGRA_PIN_DISABLE>;
				nvidia,enable-input = <TEGRA_PIN_ENABLE>;
			};

			temp_alert_px4 {
				nvidia,pins = "temp_alert_px4";
				nvidia,function = "rsvd0";
				nvidia,pull = <TEGRA_PIN_PULL_UP>;
				nvidia,tristate = <TEGRA_PIN_DISABLE>;
				nvidia,enable-input = <TEGRA_PIN_ENABLE>;
			};
		};

		pinmux_unused_lowpower: unused_lowpower {
			qspi_io0 {
				nvidia,pins = "qspi_io0";
				nvidia,function = "rsvd1";
				nvidia,pull = <TEGRA_PIN_PULL_DOWN>;
				nvidia,tristate = <TEGRA_PIN_ENABLE>;
				nvidia,enable-input = <TEGRA_PIN_DISABLE>;
			};

			qspi_io1 {
				nvidia,pins = "qspi_io1";
				nvidia,function = "rsvd1";
				nvidia,pull = <TEGRA_PIN_PULL_DOWN>;
				nvidia,tristate = <TEGRA_PIN_ENABLE>;
				nvidia,enable-input = <TEGRA_PIN_DISABLE>;
			};

			qspi_sck {
				nvidia,pins = "qspi_sck";
				nvidia,function = "rsvd1";
				nvidia,pull = <TEGRA_PIN_PULL_DOWN>;
				nvidia,tristate = <TEGRA_PIN_ENABLE>;
				nvidia,enable-input = <TEGRA_PIN_DISABLE>;
			};

			qspi_cs_n {
				nvidia,pins = "qspi_cs_n";
				nvidia,function = "rsvd1";
				nvidia,pull = <TEGRA_PIN_PULL_DOWN>;
				nvidia,tristate = <TEGRA_PIN_ENABLE>;
				nvidia,enable-input = <TEGRA_PIN_DISABLE>;
			};

			qspi_io2 {
				nvidia,pins = "qspi_io2";
				nvidia,function = "rsvd1";
				nvidia,pull = <TEGRA_PIN_PULL_DOWN>;
				nvidia,tristate = <TEGRA_PIN_ENABLE>;
				nvidia,enable-input = <TEGRA_PIN_DISABLE>;
			};

			qspi_io3 {
				nvidia,pins = "qspi_io3";
				nvidia,function = "rsvd1";
				nvidia,pull = <TEGRA_PIN_PULL_DOWN>;
				nvidia,tristate = <TEGRA_PIN_ENABLE>;
				nvidia,enable-input = <TEGRA_PIN_DISABLE>;
			};

			gps_rst_pi3 {
				nvidia,pins = "gps_rst_pi3";
				nvidia,function = "rsvd0";
				nvidia,pull = <TEGRA_PIN_PULL_DOWN>;
				nvidia,tristate = <TEGRA_PIN_ENABLE>;
				nvidia,enable-input = <TEGRA_PIN_DISABLE>;
			};

			gpio_x3_aud {
				nvidia,pins = "gpio_x3_aud";
				nvidia,function = "rsvd0";
				nvidia,pull = <TEGRA_PIN_PULL_DOWN>;
				nvidia,tristate = <TEGRA_PIN_ENABLE>;
				nvidia,enable-input = <TEGRA_PIN_DISABLE>;
			};

			clk_req {
				nvidia,pins = "clk_req";
				nvidia,function = "rsvd1";
				nvidia,pull = <TEGRA_PIN_PULL_DOWN>;
				nvidia,tristate = <TEGRA_PIN_ENABLE>;
				nvidia,enable-input = <TEGRA_PIN_DISABLE>;
			};

			pl0 {
				nvidia,pins = "pl0";
				nvidia,function = "rsvd0";
				nvidia,pull = <TEGRA_PIN_PULL_DOWN>;
				nvidia,tristate = <TEGRA_PIN_ENABLE>;
				nvidia,enable-input = <TEGRA_PIN_DISABLE>;
			};

			pcc7 {
				nvidia,pins = "pcc7";
				nvidia,function = "rsvd0";
				nvidia,pull = <TEGRA_PIN_PULL_DOWN>;
				nvidia,tristate = <TEGRA_PIN_ENABLE>;
				nvidia,enable-input = <TEGRA_PIN_DISABLE>;
				nvidia,io-high-voltage = <TEGRA_PIN_DISABLE>;
			};

			spdif_out_pcc2 {
				nvidia,pins = "spdif_out_pcc2";
				nvidia,function = "rsvd1";
				nvidia,pull = <TEGRA_PIN_PULL_DOWN>;
				nvidia,tristate = <TEGRA_PIN_ENABLE>;
				nvidia,enable-input = <TEGRA_PIN_DISABLE>;
			};

			spdif_in_pcc3 {
				nvidia,pins = "spdif_in_pcc3";
				nvidia,function = "rsvd1";
				nvidia,pull = <TEGRA_PIN_PULL_DOWN>;
				nvidia,tristate = <TEGRA_PIN_ENABLE>;
				nvidia,enable-input = <TEGRA_PIN_DISABLE>;
			};
		};

		drive_default: drive {
		};
	};
};
